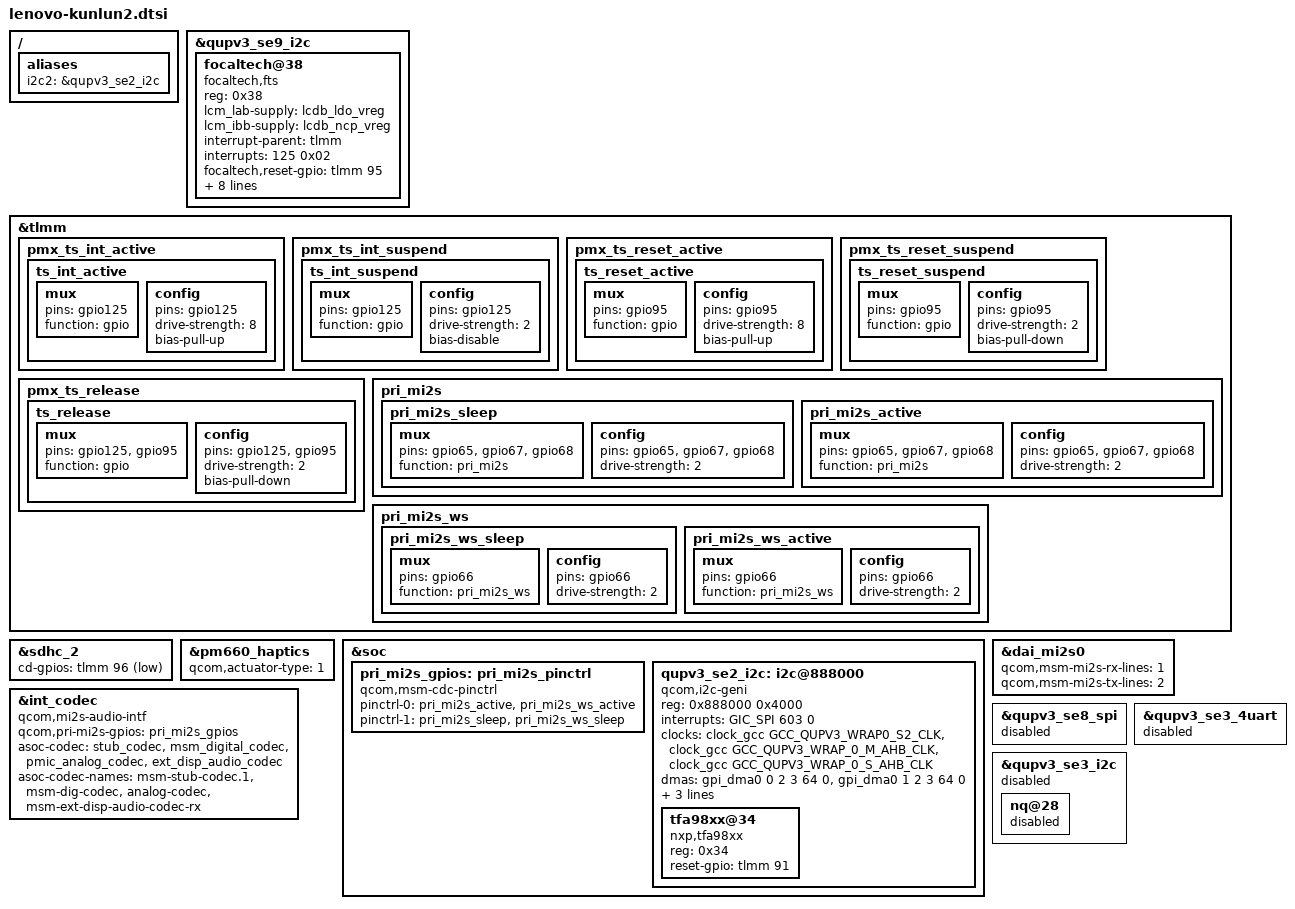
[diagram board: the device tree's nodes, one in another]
/* Copyright (c) 2016-2017, The Linux Foundation. All rights reserved.
 *
 * This program is free software; you can redistribute it and/or modify
 * it under the terms of the GNU General Public License version 2 and
 * only version 2 as published by the Free Software Foundation.
 *
 * This program is distributed in the hope that it will be useful,
 * but WITHOUT ANY WARRANTY; without even the implied warranty of
 * MERCHANTABILITY or FITNESS FOR A PARTICULAR PURPOSE.  See the
 * GNU General Public License for more details.
 */

//add by gongdb for kunlun2 touch panel begin
&qupv3_se9_i2c {
    status = "ok";
        focaltech@38{
        status = "ok";
                compatible = "focaltech,fts";
                reg = <0x38>;
                lcm_lab-supply = <&lcdb_ldo_vreg>;
                lcm_ibb-supply = <&lcdb_ncp_vreg>;
                interrupt-parent = <&tlmm>;
                interrupts = <125 0x02>;
                focaltech,reset-gpio = <&tlmm 95 0x00>;
                focaltech,irq-gpio = <&tlmm 125 0x2002>;
                vdd-supply = <&pm660l_l6>;
                vcc_i2c-supply = <&pm660_l11>;
                focaltech,max-touch-number = <10>;
                focaltech,display-coords =  <0 0 1080 2340>;

                pinctrl-names = "pmx_ts_active","pmx_ts_suspend","pmx_ts_release";
                pinctrl-0 = <&ts_int_active &ts_reset_active>;
                pinctrl-1 = <&ts_int_suspend &ts_reset_suspend>;
                pinctrl-2 = <&ts_release>;

                //focaltech,have-key;
                //focaltech,key-number = <3>;
                //focaltech,keys = <139 102 158>;
                //focaltech,key-y-coord = <2000>;
                //focaltech,key-x-coords = <200 600 800>;
        };

};

&tlmm {
               pmx_ts_int_active {
                        ts_int_active: ts_int_active {
                                   mux {
                                           pins = "gpio125";
                                           function = "gpio";
                                   };

                                   config {
                                           pins = "gpio125";
                                           drive-strength = <8>;
                                           bias-pull-up;
                                   };
                           };
                };

                pmx_ts_int_suspend {
                        ts_int_suspend: ts_int_suspend {
                                mux {
                                        pins = "gpio125";
                                        function = "gpio";
                                };

                                config {
                                        pins = "gpio125";
                                        drive-strength = <2>;
                                        bias-disable;
                                };
                        };
                };
                pmx_ts_reset_active {
                        ts_reset_active: ts_reset_active {
                                         mux {
                                                 pins = "gpio95";
                                                 function = "gpio";
                                         };

                                         config {
                                                 pins = "gpio95";
                                                 drive-strength = <8>;
                                                 bias-pull-up;
                                         };
                                 };
                };



                pmx_ts_reset_suspend {
                        ts_reset_suspend: ts_reset_suspend {
                                mux {
                                        pins = "gpio95";
                                        function = "gpio";
                                };

                                config {
                                        pins = "gpio95";
                                        drive-strength = <2>;
                                        bias-pull-down;
                                };
                        };
                };
                pmx_ts_release {
                        ts_release: ts_release {
                                mux {
                                        pins = "gpio125", "gpio95";
                                        function = "gpio";
                                };

                                config {
                                        pins = "gpio125", "gpio95";
                                        drive-strength = <2>;
                                        bias-pull-down;
                                };
                        };
                };

};
//add by gongdb for kunlun2 touch panel end

//add by gongdb for kunlun2 sdcard detect begin
&sdhc_2 {
	cd-gpios = <&tlmm 96 0x1>;
};
//add by gongdb for kunlun2 sdcard detect end

//add by gongdb for kunlun2 vibrator begin
&pm660_haptics {
	qcom,actuator-type = <1>;
        status = "okay";
};
//add by gongdb for kunlun2 vibrator end

//add by huanghuan5 for kunlun audio start
&tlmm {
                  pri_mi2s {
			pri_mi2s_sleep: pri_mi2s_sleep {
				mux {
				pins = "gpio65","gpio67","gpio68";
				function = "pri_mi2s";
				};

				config {
				pins = "gpio65","gpio67","gpio68";
				drive-strength = <2>; /* 2 mA */
				};
			};

			pri_mi2s_active: pri_mi2s_active {
			 mux {
				 pins = "gpio65","gpio67","gpio68";
				 function = "pri_mi2s";
			 };
			 config {
				 pins = "gpio65","gpio67","gpio68";
				 drive-strength = <2>; /* 8 mA */
			 };
		 };
		};

		pri_mi2s_ws {
			pri_mi2s_ws_sleep: pri_mi2s_ws_sleep {
			   mux {
				   pins = "gpio66";
				   function = "pri_mi2s_ws";
			   };

			   config {
				   pins = "gpio66";
				   drive-strength = <2>; /* 2 mA */
			   };
		   };

			pri_mi2s_ws_active: pri_mi2s_ws_active {
			    mux {
				    pins = "gpio66";
				    function = "pri_mi2s_ws";
			    };
			    config {
				    pins = "gpio66";
				    drive-strength = <2>; /* 8 mA */
			    };
		    };
		};

};
&soc {	

        pri_mi2s_gpios: pri_mi2s_pinctrl {
               status = "ok";
               compatible = "qcom,msm-cdc-pinctrl";
               pinctrl-names = "aud_active", "aud_sleep";
               pinctrl-0 = <&pri_mi2s_active &pri_mi2s_ws_active>;
               pinctrl-1 = <&pri_mi2s_sleep &pri_mi2s_ws_sleep>;
	};
	

      	qupv3_se2_i2c: i2c@888000 {
		compatible = "qcom,i2c-geni";
		reg = <0x888000 0x4000>;
		interrupts = <GIC_SPI 603 0>;
		#address-cells = <1>;
		#size-cells = <0>;
		clock-names = "se-clk", "m-ahb", "s-ahb";
		clocks = <&clock_gcc GCC_QUPV3_WRAP0_S2_CLK>,
			<&clock_gcc GCC_QUPV3_WRAP_0_M_AHB_CLK>,
			<&clock_gcc GCC_QUPV3_WRAP_0_S_AHB_CLK>;
		dmas = <&gpi_dma0 0 2 3 64 0>,
			<&gpi_dma0 1 2 3 64 0>;
		dma-names = "tx", "rx";
		pinctrl-names = "default", "sleep";
		pinctrl-0 = <&qupv3_se2_i2c_active>;
		pinctrl-1 = <&qupv3_se2_i2c_sleep>;
		qcom,wrapper-core = <&qupv3_0>;
		status = "ok";
	};
};
&dai_mi2s0 {
     qcom,msm-mi2s-rx-lines = <1>;
     qcom,msm-mi2s-tx-lines = <2>;
     };

	   

&int_codec {
     qcom,mi2s-audio-intf;
     qcom,pri-mi2s-gpios = <&pri_mi2s_gpios>;
     asoc-codec = <&stub_codec>, <&msm_digital_codec>,
     	          <&pmic_analog_codec>,<&ext_disp_audio_codec>;
     asoc-codec-names = "msm-stub-codec.1", "msm-dig-codec",
                        "analog-codec", "msm-ext-disp-audio-codec-rx";
};
&qupv3_se8_spi {
     status = "disabled";       
};
&qupv3_se2_i2c {
	status = "ok";
		tfa98xx@34 {
		        compatible = "nxp,tfa98xx";
			reg = <0x34>;
			reset-gpio= <&tlmm 91 0>;
	        };
	};
	
/ {
	aliases {
	i2c2 = &qupv3_se2_i2c;
	};
};

//add by huanghuan5 for kunlun audio end

/*hdbd gps*/
&qupv3_se3_4uart {
	status = "disabled";
};

&qupv3_se3_i2c {
	status = "disabled";
	nq@28 {
		status = "disabled";
	};
};
